# wsoc_intr_ctrl_secure register map
Vendor: Texas Instruments
Peripheral module from a debugger description file (folder CC35X1).
Registers are 32-bit, write-only, reset 0x0 unless marked. A register's access mark holds for its fields unless they carry their own. Offsets are as the file gives them; lines under a group give offsets from that group; [hi:lo] are bit positions; {n}, {i} and the like mark numbered series; 'fields as' and 'values as' point back to an identical list; <NAME> marks a mode.

## wsoc_intr_ctrl_secure
0x00 irq0_mask_l rw — IRQ0 Mask (IRQ0_MASK_L) Registers Mask for 32 of 64 triggers 1 - Masked (Interupt Disabled) 2 - Not Masked (Interrupt enabled)
  [31:0] IRQ0_MASK_L_WROPT
0x04 irq0_mask_h rw — IRQ0 Mask (IRQ0_MASK_H) Registers [63:32] Mask for 32 of 64 triggers 1 - Masked (Interupt Disabled) 0 - Not Masked (Interrupt enabled)
  [31:0] IRQ0_MASK_H_WROPT
    1=disabled. masked;0 = corresponding interrupt is enabled for ARM Fast Interrupt Request (IRQ0)
0x08 irq0_mask_set_l — IRQ0 Mask Set (IRQ0_MASK_SET_L) Registers [31:0] Set mask bits in IRQ0_MASK Register 1 Set mask bit 0 No Change
  [31:0] IRQ0_MASK_SET_L_WRCL
    1=WRITEVALUE_1 (set corresponding bit in IRQ0 Interrupt Mask register;0 = no effect)
0x0C irq0_mask_set_h — IRQ0 Mask Set (IRQ0_MASK_SET_H) Registers [63:32] Set mask bits in IRQ0_MASK Register 1 Set mask bit 0 No Change
  [31:0] IRQ0_MASK_SET_H_WRCL
    values as irq0_mask_set_l.IRQ0_MASK_SET_L_WRCL
0x10 irq0_mask_clr_l — IRQ0 Mask Clear (IRQ0_MASK_CLR_L) Registers [31:0] Clear mask bits of register IRQ0_MASK_L 1 - Clear Mask 0 - No change
  [31:0] IRQ0_MASK_CLR_L_WRCL
    1=WRITEVALUE_1 (clear corresponding bit in IRQ0 Interrupt Mask register;0 = no effect)
0x14 irq0_mask_clr_h — IRQ0 Mask Clear (IRQ0_MASK_CLR_H) Registers [63:32] Clear mask bits of register IRQ0_MASK_H 1 - Clear Mask 0 - No change
  [31:0] IRQ0_MASK_CLR_H_WRCL
    values as irq0_mask_clr_l.IRQ0_MASK_CLR_L_WRCL
0x18 irq0_mis_l ro — IRQ0 Interrupt Status (IRQ0_STS_L) Registers [31:0] Read Interupt_Status register with IRQ0_MASK
  [31:0] IRQ0_MIS_L
    1=READVALUE_1 (corresponding unmasked Interrupt is pending;0 = corresponding interrupt is inactive or masked by IRQ0 MASK)
0x1C irq0_mis_h ro — IRQ0 Interrupt Status (IRQ0_STS_H) Registers [63:32] Read Interupt_Status register with IRQ0_MASK
  [31:0] IRQ0_MIS_H
    values as irq0_mis_l.IRQ0_MIS_L
0x20 irq1_mask_l rw — IRQ Mask (IRQ1_MASK_L) Registers [31:0] Mask for 32 of 64 triggers 1 - Masked (Interupt Disabled) 2 - Not Masked (Interrupt enabled)
  [31:0] IRQ1_MASK_L_WROPT
    1=disabled. masked;0 = corresponding interrupt is enabled for ARM Interrupt Request (IRQ)
0x24 irq1_mask_h rw — IRQ Mask (IRQ1_MASK_H) Registers [63:32] Mask for 32 of 64 triggers 1 - Masked (Interupt Disabled) 0 - Not Masked (Interrupt enabled)
  [31:0] IRQ1_MASK_H_WROPT
    values as irq1_mask_l.IRQ1_MASK_L_WROPT
0x28 irq1_mask_set_l — IRQ Mask Set (IRQ1_MASK_SET_L) Registers [31:0] RQ Mask Set (IRQ_MASK_SET_H) Registers [63:32] Set mask bits of register IRQ_MASK 1 - Set Mask 0 - No change
  [31:0] IRQ1_MASK_SET_L_WRCL
    1=WRITEVALUE_1 (set corresponding bit in IRQ Interrupt Mask register;0 = no effect)
0x2C irq1_mask_set_h — IRQ Mask Set (IRQ1_MASK_SET_H) Registers [63:32] Set mask bits of register IRQ_MASK 1 - Set Mask 0 - No change
  [31:0] IRQ1_MASK_SET_H_WRCL
    values as irq1_mask_set_l.IRQ1_MASK_SET_L_WRCL
0x30 irq1_mask_clr_l — IRQ Mask Clear (IRQ1_MASK_CLR_L) Registers [31:0] Clear mask bits of register IRQ_MASK_L 1 - Clear Mask 0 - No change
  [31:0] IRQ1_MASK_CLR_L_WRCL
    1=WRITEVALUE_1 (clear corresponding bit in IRQ Interrupt Mask register;0 = no effect)
0x34 irq1_mask_clr_h — IRQ Mask Clear (IRQ1_MASK_CLR_H) Registers [63:32] Clear mask bits of register IRQ_MASK_H 1 - Clear Mask 0 - No change
  [31:0] IRQ1_MASK_CLR_H_WRCL
    values as irq1_mask_clr_l.IRQ1_MASK_CLR_L_WRCL
0x38 irq1_mis_l ro — Masked IRQ1 Interrupt Status (IRQ1_STS_L) Registers [31:0] Read Interupt_Status register with IRQ_MASK
  [31:0] IRQ1_MIS_L
    1=READVALUE_1 (corresponding unmasked Interrupt is pending;0 = corresponding interrupt is inactive or masked by IRQ MASK)
0x3C irq1_mis_h ro — IRQ Interrupt Status (IRQ1_STS_H) Registers [63:32] Read Interupt_Status register with IRQ_MASK
  [31:0] IRQ1_MIS_H
    values as irq1_mis_l.IRQ1_MIS_L
0x40 irq2_mask_l rw — IRQ2 Mask (IRQ2_MASK_L) Registers Mask for 32 of 64 triggers 1 - Masked (Interupt Disabled) 2 - Not Masked (Interrupt enabled)
  [31:0] IRQ2_MASK_L_WROPT
    1=disabled. masked;0 = corresponding interrupt is enabled for ARM Fast Interrupt Request (IRQ2)
0x44 irq2_mask_h rw — IRQ2 Mask (IRQ2_MASK_H) Registers [63:32] Mask for 32 of 64 triggers 1 - Masked (Interupt Disabled) 0 - Not Masked (Interrupt enabled)
  [31:0] IRQ2_MASK_H_WROPT
    values as irq2_mask_l.IRQ2_MASK_L_WROPT
0x48 irq2_mask_set_l — IRQ2 Mask Set (IRQ2_MASK_SET_L) Registers [31:0] Set mask bits in IRQ2_MASK Register 1 Set mask bit 0 No Change
  [31:0] IRQ2_MASK_SET_L_WRCL
    1=WRITEVALUE_1 (set corresponding bit in IRQ2 Interrupt Mask register;0 = no effect)
0x4C irq2_mask_set_h — IRQ2 Mask Set (IRQ2_MASK_SET_H) Registers [63:32] Set mask bits in IRQ2_MASK Register 1 Set mask bit 0 No Change
  [31:0] IRQ2_MASK_SET_H_WRCL
    values as irq2_mask_set_l.IRQ2_MASK_SET_L_WRCL
0x50 irq2_mask_clr_l — IRQ2 Mask Clear (IRQ2_MASK_CLR_L) Registers [31:0] Clear mask bits of register IRQ2_MASK_L 1 - Clear Mask 0 - No change
  [31:0] IRQ2_MASK_CLR_L_WRCL
    1=WRITEVALUE_1 (clear corresponding bit in IRQ2 Interrupt Mask register;0 = no effect)
0x54 irq2_mask_clr_h — IRQ2 Mask Clear (IRQ2_MASK_CLR_H) Registers [63:32] Clear mask bits of register IRQ2_MASK_H 1 - Clear Mask 0 - No change
  [31:0] IRQ2_MASK_CLR_H_WRCL
    values as irq2_mask_clr_l.IRQ2_MASK_CLR_L_WRCL
0x58 irq2_mis_l ro — IRQ2 Interrupt Status (IRQ2_STS_L) Registers [31:0] Read Interupt_Status register with IRQ2_MASK
  [31:0] IRQ2_MIS_L
    1=READVALUE_1 (corresponding unmasked Interrupt is pending;0 = corresponding interrupt is inactive or masked by IRQ2 MASK)
0x5C irq2_mis_h ro — IRQ2 Interrupt Status (IRQ2_STS_H) Registers [63:32] Read Interupt_Status register with IRQ2_MASK
  [31:0] IRQ2_MIS_H
    values as irq2_mis_l.IRQ2_MIS_L
0xA0 ris_l ro — Raw Interrupt Status (previously INT_STS_RAW_L) Register [31:0] Read Interupt_Status register umasked
  [31:0] INT_STS_L
    1=READVALUE_1 (corresponding Interrupt is pending;0 = corresponding interrupt is inactive)
0xA4 ris_h ro — Raw Interrupt Status (previously INT_STS_RAW_H) Register Low [63:32] Read Interupt_Status register umasked
  [31:0] INT_STS_H
    values as ris_l.INT_STS_L
0xA8 int_ack_l — Acknowledge (INT_ACK_L) Registers Acknowledge for any bit of INT_STS [31:0] 1 - Acknoledge (Interupt bit of INT STS is set to 0) 0 - No change
  [31:0] INT_ACK_L_WRCL
    1=WRITEVALUE_1 (corresponding Interrupt clears on write;0 = corresponding interrupt is not disturbed)
0xAC int_ack_h — Interrupt Acknowledge (INT_ACK_H) Registers [63:32] Acknowledge for any bit of INT_STS [63:32] 1 - Acknoledge (Interupt bit of NT STS is set to 0) 0 - No change
  [31:0] INT_ACK_H_WRCL
    values as int_ack_l.INT_ACK_L_WRCL
0xB0 int_trig_l — Interrupt Trigger (INT_TRIG_L) Registers [31:0] Setting each interupt bit of INT_STS as following 1 Set to 1 (Interrupt happend) 0 No change In any case INT_STS will be updated due to the hardware triggers
  [31:0] INT_TRIG_L_WRCL
    1=WRITEVALUE_1 (corresponding Interrupt is activated [except for indirect interrupts. bits 30.31 and 51];0 = corresponding interrupt is not disturbed)
0xB4 int_trig_h — Interrupt Trigger (INT_TRIG_H) Registers [63:32] Setting each interupt bit of INT_STS as following 1 Set to 1 (Interrupt happend) 0 No change In any case INT_STS will be updated due to the hardware triggers
  [31:0] INT_TRIG_H_WRCL
    values as int_trig_l.INT_TRIG_L_WRCL
0xB8 ris_clr_l ro — Interrupt Status Clear (RIS_CLR_L) Registers [31:0] Clears all bits of INT_STS register In any case INT_STS will be updated due to the hardware triggers
  [31:0] RIS_CLR_L_RDCL — Clears on Read.;1 = corresponding Interrupt is pending;0 = corresponding interrupt is inactive
0xBC ris_clr_h ro — Interrupt Status Clear (RIS_CLR_H) Registers [63:32] Clears all bits of INT_STS register In any case INT_STS will be updated due to the hardware triggers
  [31:0] RIS_CLR_H_RDCL — Clears on Read.;1 = corresponding Interrupt is pending;0 = corresponding interrupt is inactive
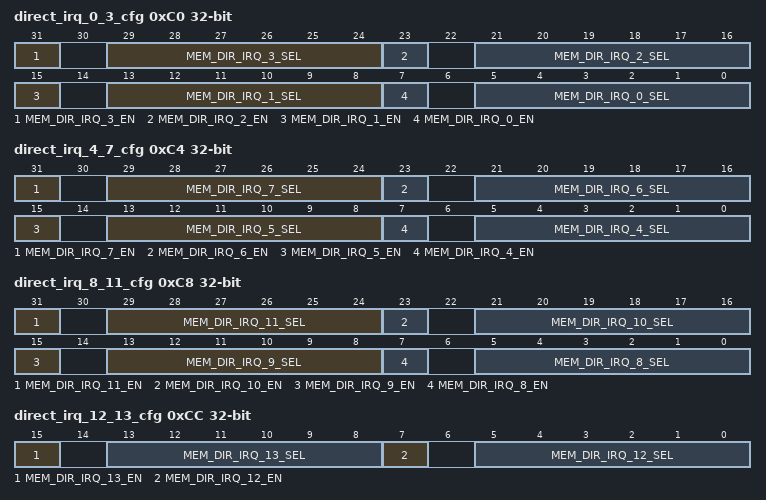
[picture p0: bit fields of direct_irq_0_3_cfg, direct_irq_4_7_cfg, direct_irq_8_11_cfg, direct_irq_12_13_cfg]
0xC0 direct_irq_0_3_cfg access per field — defines 4 direct interrupt lines (mapped to direct sources 0 to 3)
  [31] MEM_DIR_IRQ_3_EN rw — interrupt 3 enable. 0: interrupt disabled, 1: interrupt enabled
  [8n+5:8n] MEM_DIR_IRQ_{n}_SEL rw (n=0..3) — interrupt {n} source index
  [23] MEM_DIR_IRQ_2_EN rw — interrupt 2 source enable. 0: interrupt disabled, 1: interrupt enabled
  [15] MEM_DIR_IRQ_1_EN rw — interrupt 1 enable. 0: interrupt disable, 1: interrupt enabled
  [7] MEM_DIR_IRQ_0_EN rw — interrupt 0 enable. 0: interrupt disable, 1: interrupt enabled
0xC4 direct_irq_4_7_cfg access per field — defines 4 direct interrupt lines (mapped to direct sources 3 to 7)
  [31] MEM_DIR_IRQ_7_EN rw — interrupt 7 enable. 0: interrupt disabled, 1: interrupt enabled
  [8n-27:8n-32] MEM_DIR_IRQ_{n}_SEL rw (n=4..7) — interrupt {n} source index
  [23] MEM_DIR_IRQ_6_EN rw — interrupt 6 source enable. 0: interrupt disabled, 1: interrupt enabled
  [15] MEM_DIR_IRQ_5_EN rw — interrupt 5 enable. 0: interrupt disable, 1: interrupt enabled
  [7] MEM_DIR_IRQ_4_EN rw — interrupt 4 enable. 0: interrupt disable, 1: interrupt enabled
0xC8 direct_irq_8_11_cfg access per field — defines 4 direct interrupt lines (mapped to direct sources 8 to 11)
  [31] MEM_DIR_IRQ_11_EN rw — interrupt 11 enable. 0: interrupt disabled, 1: interrupt enabled
  [8n-59:8n-64] MEM_DIR_IRQ_{n}_SEL rw (n=8..11) — interrupt {n} source index
  [23] MEM_DIR_IRQ_10_EN rw — interrupt 10 source enable. 0: interrupt disabled, 1: interrupt enabled
  [15] MEM_DIR_IRQ_9_EN rw — interrupt 9 enable. 0: interrupt disable, 1: interrupt enabled
  [7] MEM_DIR_IRQ_8_EN rw — interrupt 8 enable. 0: interrupt disable, 1: interrupt enabled
0xCC direct_irq_12_13_cfg access per field — defines 2 direct interrupt lines (mapped to direct sources 12 to 13)
  [15] MEM_DIR_IRQ_13_EN rw — interrupt 13 enable. 0: interrupt disable, 1: interrupt enabled
  [13:8] MEM_DIR_IRQ_13_SEL rw — interrupt 9 source index
  [7] MEM_DIR_IRQ_12_EN rw — interrupt 12 enable. 0: interrupt disable, 1: interrupt enabled
  [5:0] MEM_DIR_IRQ_12_SEL rw — interrupt 12 source index
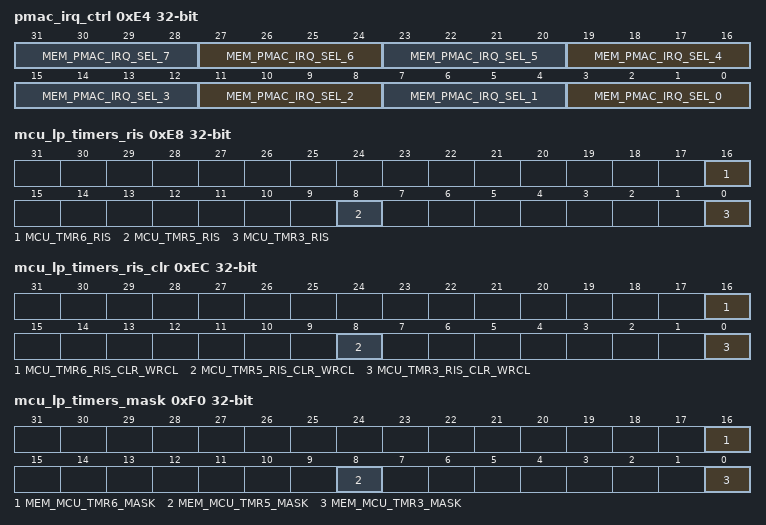
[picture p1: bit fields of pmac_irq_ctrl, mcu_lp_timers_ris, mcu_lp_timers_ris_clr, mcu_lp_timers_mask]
0xE4 pmac_irq_ctrl rw — IRQ selection list: Bit 12 - wsoc_rx_trigger_frame_irq Bit 11 - wmac_tx_cand_done_irq Bit 10 - wmac_scrpt_irq1 Bit 9 - wmac_scrpt_irq0 Bit 8 - wmac_tx_exch_done_irq Bit 7 - wmac_ppdu_abort_irq Bit 6 - wmac_rxcmd_header_irq Bit 5 - wmac_rx_suspended_irq Bit 4 - wmac_phy_hdr_start_irq Bit 3 - wmac_tx_trigger_irq Bit 2 - wmac_rx_time_out_irq Bit 1 - wmac_rx_complete_irq Bit 0 - wmac_tx_stop_irq
  [4n+3:4n] MEM_PMAC_IRQ_SEL_{n} (n=0..7) — select the pmac source to be connected as an interrupt trigger.
0xE8 mcu_lp_timers_ris ro — raw interrupt status for timers 3,5,6 aggregated interrupt source.
  [16] MCU_TMR6_RIS, [8] MCU_TMR5_RIS, [0] MCU_TMR3_RIS
0xEC mcu_lp_timers_ris_clr access per field — writing 1 to a bit will clear the RIS. writing 0 will be ignored.
  [16] MCU_TMR6_RIS_CLR_WRCL wo, [8] MCU_TMR5_RIS_CLR_WRCL wo, [0] MCU_TMR3_RIS_CLR_WRCL wo
0xF0 mcu_lp_timers_mask access per field — MCU Timers 3,5,6 Interrupt mask.
  [16] MEM_MCU_TMR6_MASK rw, [8] MEM_MCU_TMR5_MASK rw, [0] MEM_MCU_TMR3_MASK rw
0xF4 fifo_cnc1_blk3_mask access per field
  [7:3] MEM_FIFO_CNC1_BLK3_MASK rw — Bit mask for BLK fifo concentrator.
0xF8 fifo_cnc2_blk3_mask access per field
  [7:3] MEM_FIFO_CNC2_BLK3_MASK rw — Bit mask for BLK fifo concentrator.
0xFC fifo_cnc1_blk5_mask access per field
  [9:0] MEM_FIFO_CNC1_BLK5_MASK rw — Bit mask for BLK fifo concentrator.
0x100 fifo_cnc2_blk5_mask access per field
  [9:0] MEM_FIFO_CNC2_BLK5_MASK rw — Bit mask for BLK fifo concentrator.
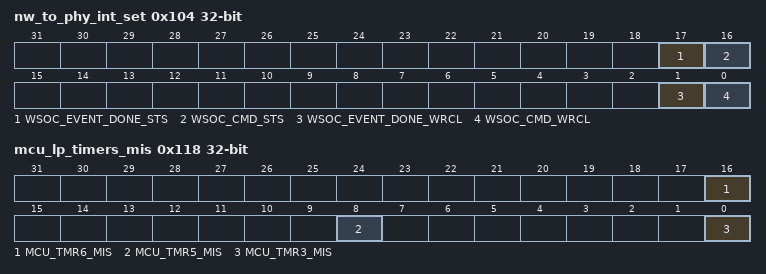
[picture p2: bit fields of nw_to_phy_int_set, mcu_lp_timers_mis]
0x104 nw_to_phy_int_set access per field
  [17] WSOC_EVENT_DONE_STS ro — current state of the toggle signal. for debug only. actual state does not mean and interrupt is asserted as only a change is detected at the phy.
  [16] WSOC_CMD_STS ro — current state of the toggle signal. for debug only. actual state does not mean and interrupt is asserted as only a change is detected at the phy.
  [1] WSOC_EVENT_DONE_WRCL wo — writing 1 to this bit toggle the signal wsoc_event_done towards the phy. the toggle signal will be derived in the phy to detect rise/fall.
  [0] WSOC_CMD_WRCL wo — writing 1 to this bit toggle the signal wsoc_cmd towards the phy. the toggle signal will be derived in the phy to detect rise/fall.
0x108 elp_wakeup_evt_ris ro
  [16:0] ELP_WAKEUP_EVT_RIS — Bit 0 : tmr_wakeup_req Bit 1 : hif_wakeup_int Bit 2 : gpio_wakeup_src[0] Bit 3 : gpio_wakeup_src[1] Bit 4 : evt_mng_m3_irq0 Bit 5 : evt_mng_m3_irq1 Bit 6 : evt_mng_m3_irq2 Bit 7 : evt_mng_m3_irq3 Bit 8 : evt_mng_m3_irq4 Bit 9 : evt_mng_m3_irq5 Bit 10 : evt_mng_m3_irq6 Bit 11 : evt_mng_m3_irq7 Bit 12 : evt_mng_m3_irq8 Bit 13 : evt_mng_m3_irq9 Bit 14 : mem_ns_sw_interrupt_to_cm3 Bit 15 : mem_sec_sw_interrupt_to_cm3 Bit 16 : debugss_core_forceactive
0x10C elp_wakeup_evt_ris_clr access per field — writing 1 to a bit will clear the RIS. writing 0 will be ignored.
  [16:0] ELP_WAKEUP_EVT_RIS_CLR_WRCL wo — Bit 0 : tmr_wakeup_req Bit 1 : hif_wakeup_int Bit 2 : gpio_wakeup_src[0] Bit 3 : gpio_wakeup_src[1] Bit 4 : evt_mng_m3_irq0 Bit 5 : evt_mng_m3_irq1 Bit 6 : evt_mng_m3_irq2 Bit 7 : evt_mng_m3_irq3 Bit 8 : evt_mng_m3_irq4 Bit 9 : evt_mng_m3_irq5 Bit 10 : evt_mng_m3_irq6 Bit 11 : evt_mng_m3_irq7 Bit 12 : evt_mng_m3_irq8 Bit 13 : evt_mng_m3_irq9 Bit 14 : mem_ns_sw_interrupt_to_cm3 Bit 15 : mem_sec_sw_interrupt_to_cm3 Bit 16 : debugss_core_forceactive
0x110 elp_wakeup_evt_mask access per field — Set 1 - Mask event. Set 0 - Otherwise.
  [16:0] MEM_ELP_WAKEUP_EVT_MASK rw — Bit 0 : tmr_wakeup_req Bit 1 : hif_wakeup_int Bit 2 : gpio_wakeup_src[0] Bit 3 : gpio_wakeup_src[1] Bit 4 : evt_mng_m3_irq0 Bit 5 : evt_mng_m3_irq1 Bit 6 : evt_mng_m3_irq2 Bit 7 : evt_mng_m3_irq3 Bit 8 : evt_mng_m3_irq4 Bit 9 : evt_mng_m3_irq5 Bit 10 : evt_mng_m3_irq6 Bit 11 : evt_mng_m3_irq7 Bit 12 : evt_mng_m3_irq8 Bit 13 : evt_mng_m3_irq9 Bit 14 : mem_ns_sw_interrupt_to_cm3 Bit 15 : mem_sec_sw_interrupt_to_cm3 Bit 16 : debugss_core_forceactive
0x114 elp_wakeup_evt_mis ro — Masked Interrupt Status
  [16:0] ELP_WAKEUP_EVT_MIS — Bit 0 : tmr_wakeup_req Bit 1 : hif_wakeup_int Bit 2 : gpio_wakeup_src[0] Bit 3 : gpio_wakeup_src[1] Bit 4 : evt_mng_m3_irq0 Bit 5 : evt_mng_m3_irq1 Bit 6 : evt_mng_m3_irq2 Bit 7 : evt_mng_m3_irq3 Bit 8 : evt_mng_m3_irq4 Bit 9 : evt_mng_m3_irq5 Bit 10 : evt_mng_m3_irq6 Bit 11 : evt_mng_m3_irq7 Bit 12 : evt_mng_m3_irq8 Bit 13 : evt_mng_m3_irq9 Bit 14 : mem_ns_sw_interrupt_to_cm3 Bit 15 : mem_sec_sw_interrupt_to_cm3 Bit 16 : debugss_core_forceactive
0x118 mcu_lp_timers_mis ro — masked interrupt status for timers 3,5,6 aggregated interrupt source.
  [16] MCU_TMR6_MIS, [8] MCU_TMR5_MIS, [0] MCU_TMR3_MIS
